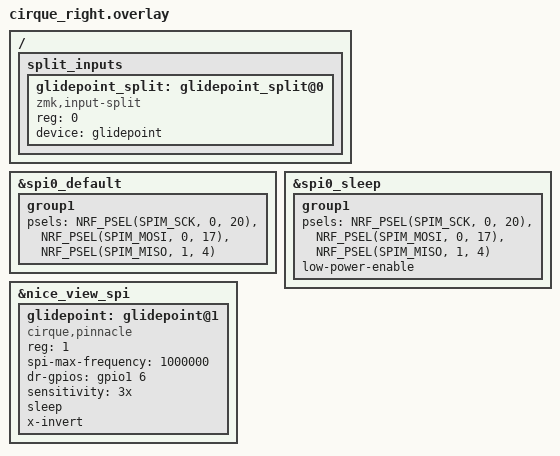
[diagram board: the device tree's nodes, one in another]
/*
 * Trackpad Cirque GlidePoint por SPI en la mitad derecha (periférico).
 * Comparte el bus spi0 del nice!view (SCK=P0.20, MOSI=P0.17) y agrega:
 *   MISO -> P1.04 (pad 104)   CS -> P0.09 (pad 009, NFC liberado en keymap)
 *   DR   -> P1.06 (pad 106)
 * Cableado del Cirque: SCK->020, SI->017, SO->104, SS->009, DR->106.
 */

/* Nodo input-split (los shields se procesan antes que el keymap, así que
 * cada shield define sus propios nodos; no colisionan porque cada build
 * incluye solo uno de los dos shields cirque_*). */
/ {
    split_inputs {
        #address-cells = <1>;
        #size-cells = <0>;

        glidepoint_split: glidepoint_split@0 {
            compatible = "zmk,input-split";
            reg = <0>;
        };
    };
};

&spi0_default {
    group1 {
        psels = <NRF_PSEL(SPIM_SCK, 0, 20)>,
            <NRF_PSEL(SPIM_MOSI, 0, 17)>,
            <NRF_PSEL(SPIM_MISO, 1, 4)>;
    };
};

&spi0_sleep {
    group1 {
        psels = <NRF_PSEL(SPIM_SCK, 0, 20)>,
            <NRF_PSEL(SPIM_MOSI, 0, 17)>,
            <NRF_PSEL(SPIM_MISO, 1, 4)>;
        low-power-enable;
    };
};

&nice_view_spi {
    /* cs-gpios (idx0 display, idx1 Cirque) se define en corne.keymap: el
     * keymap se procesa al final y pisaría cualquier array definido aquí. */
    glidepoint: glidepoint@1 {
        compatible = "cirque,pinnacle";
        reg = <1>;
        spi-max-frequency = <1000000>;
        status = "okay";
        dr-gpios = <&gpio1 6 GPIO_ACTIVE_HIGH>;
        sensitivity = "3x";
        sleep;
        /* El pad quedó montado espejado en X (derecha movía a la izquierda) */
        x-invert;
    };
};

&glidepoint_split {
    device = <&glidepoint>;
};
